# JPGENC0_CORE_MMU register map
Vendor: Texas Instruments
Peripheral module from a debugger description file (folder J722S).
Registers are 32-bit, read-only, reset values left out (the file's numbers can be read two ways) unless marked. A register's access mark holds for its fields unless they carry their own. Offsets are as the file gives them; lines under a group give offsets from that group; [hi:lo] are bit positions; {n}, {i} and the like mark numbered series; 'fields as' and 'values as' point back to an identical list; <NAME> marks a mode.

## JPGENC0_CORE_MMU
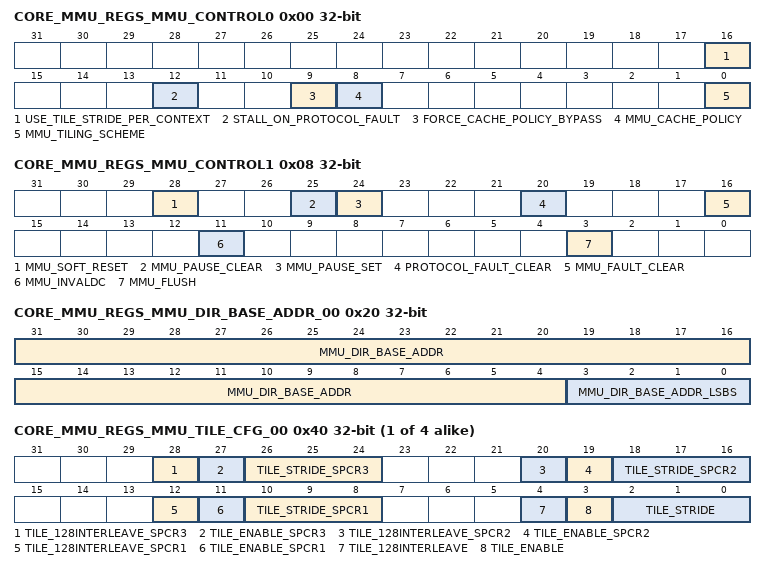
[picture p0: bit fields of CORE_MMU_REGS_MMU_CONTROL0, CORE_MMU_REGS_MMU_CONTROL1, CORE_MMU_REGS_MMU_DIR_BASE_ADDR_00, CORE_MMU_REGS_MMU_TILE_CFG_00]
0x00 CORE_MMU_REGS_MMU_CONTROL0 access per field
  [16] USE_TILE_STRIDE_PER_CONTEXT rw — 1: Separate MMU_TILE_CFG fields apply per context 0: All contexts use MMU_TILE_CFG for context 0
  [12] STALL_ON_PROTOCOL_FAULT rw — Debug only:Setting this bit to '1' causes any requestor with a protocol fault to stall
  [9] FORCE_CACHE_POLICY_BYPASS rw — Setting this bit to '1' causes all requests to external memory to have a cache policy of 0 [bypass], setting this bit to '0' passes internal cache policy to external interface
  [8] MMU_CACHE_POLICY rw — 1: MMU Directory/Page Table reads to be flagged as cacheable [external cache must have a way of flushing/tracking changes to Directory Table and Page Tables in host memory] 0: MMU reads to be flagged to bypass external cache
  [0] MMU_TILING_SCHEME rw — This bit controls the tiling scheme described in MMU Address Tiling section 0: Original tiling scheme [256-byte wide by 16 row tiles] 1: Alternative tiling scheme [512-byte wide by 8 row tiles]
0x08 CORE_MMU_REGS_MMU_CONTROL1 access per field
  [28] MMU_SOFT_RESET rw — Writing '1' to this bit causes all currently active or new memory requests to be discarded, so a reset of all active requestors is likely to also be required. External memory transactions will attempt to complete [including writing 0 data if a burst write request was sent but no corresponding data is available]. Writing '0' has no affect. Reading this field indicates if the soft reset is complete [this field will return to 0 when the soft reset is complete]
  [25] MMU_PAUSE_CLEAR rw — Writing '1' to this bit clears the pause bit, and allows new memory requests to resume. Writing '0' has no affect. Reading this field indicates if the pause bit is currently set. Setting both 'MMU_PAUSE_SET' and 'MMU_PAUSE_CLEAR' in the same write will clear the pause bit
  [24] MMU_PAUSE_SET rw — Writing '1' to this bit causes all new memory requests to pause [requests further down the pipeline will be allowed to complete]. Writing '0' has no affect. Reading this field indicates if the pause bit is currently set. Setting both 'MMU_PAUSE_SET' and 'MMU_PAUSE_CLEAR' in the same write will clear the pause bit
  [20] PROTOCOL_FAULT_CLEAR rw — Writing '1' to this bit clears all bus protocol fault flags. Writing '0' has no affect
  [16] MMU_FAULT_CLEAR rw — Writing '1' to this bit clears MMU fault [either page fault or read/write fault]. Writing '0' has no affect
  [11] MMU_INVALDC rw — For each 'dir_base_addr' used, writing '1' triggers invalidation[/flushing] of both the directory cache and page table cache for that 'dir_base_addr' [cached results for different 'dir_base_addr' can be invalidated/flushed independently]. Writing '0' has no affect
  [3] MMU_FLUSH rw — For each 'dir_base_addr' used, writing '1' triggers a flush of the Page Table cache and registered results for that 'dir_base_addr' [cached results for different 'dir_base_addr' can be flushed independently]. Writing '0' has no affect
0x10 CORE_MMU_REGS_MMU_BANK_INDEX
  [31:0] RESERVED — Specify which directory base address to use for 'group override' input n [If GROUP_OVERRIDE_SIZE is 0, this register is not used, otherwise there are '2 to the power GROUP_OVERRIDE_SIZE' entries supported in this register
0x14 CORE_MMU_REGS_EXT_REQUEST_PRIORITY_ENABLE access not given
0x18 CORE_MMU_REGS_REQUEST_PRIORITY_ENABLE
0x1C CORE_MMU_REGS_REQUEST_LIMITED_THROUGHPUT — RESERVED
0x20 CORE_MMU_REGS_MMU_DIR_BASE_ADDR_00 access per field
  [31:4] MMU_DIR_BASE_ADDR rw — Base address in physical memory for MMU Directory n Entries. When MMU_ENABLE_EXT_ADDRESSING is '1', the bits 31:0 are assigned to the address 31+EXT_ADDR_RANGE:0+EXT_ADDR_RANGE, but then any address offset within a page is forced to 0. When MMU_ENABLE_EXT_ADDRESSING is '0', bits 31:12 are assigned to address 31:12
  [3:0] MMU_DIR_BASE_ADDR_LSBS ro — Bits 3:0 of this register are read-only, and hardcoded in RTL at 0x0
{0x20+4i} CORE_MMU_REGS_MMU_DIR_BASE_ADDR_{i:02} (i=1..3)
  [31:0] MMU_DIR_BASE_ADDR — GROUP_OVERRIDE_SIZE hardcoded at 0 in RTL. Hence, this register is read only and returns 0x0
{0x40+4i} CORE_MMU_REGS_MMU_TILE_CFG_{i:02} access per field (i=0..3) — If USE_TILE_STRIDE_PER_CONTEXT is low, only the bottom byte of the register is used, and each of the four registers applies to the four regions defined by the corresponding MIN and MAX tile address ranges. If USE_TILE_STRIDE_PER_CONTEXT is high, the four bytes in a register applies to the four regions defined by the corresponding MIN and MAX tile address ranges. Then each of the four registers apply to four different contexts, where each context can use a different stride, but the MIN to MAX address range defining each region is common to all contexts (where context is the 2-bit index selected from the MMU_BANK_INDEX register).
  [28] TILE_128INTERLEAVE_SPCR3 rw — 0 : Customizable address manipulation of tiled accesses is not enabled 1 : Customizable address manipulation of tiled accesses is enabled
  [27] TILE_ENABLE_SPCR3 rw — 0 : Memory Tiling Disabled 1 : Memory Tiling Enabled
  [26:24] TILE_STRIDE_SPCR3 rw — Defines the X Tile Stride for the memory address range [stride is 2 to the power of [9+tile_stride+tiling_scheme]]
  [20] TILE_128INTERLEAVE_SPCR2 rw — 0 : Customizable address manipulation of tiled accesses is not enabled 1 : Customizable address manipulation of tiled accesses is enabled
  [19] TILE_ENABLE_SPCR2 rw — 0 : Memory Tiling Disabled 1 : Memory Tiling Enabled
  [18:16] TILE_STRIDE_SPCR2 rw — Defines the X Tile Stride for the memory address range [stride is 2 to the power of [9+tile_stride+tiling_scheme]]
  [12] TILE_128INTERLEAVE_SPCR1 rw — 0 : Customizable address manipulation of tiled accesses is not enabled 1 : Customizable address manipulation of tiled accesses is enabled
  [11] TILE_ENABLE_SPCR1 rw — 0 : Memory Tiling Disabled 1 : Memory Tiling Enabled
  [10:8] TILE_STRIDE_SPCR1 rw — Defines the X Tile Stride for the memory address range [stride is 2 to the power of [9+tile_stride+tiling_scheme]]
  [4] TILE_128INTERLEAVE rw — 0 : Customizable address manipulation of tiled accesses is not enabled 1 : Customizable address manipulation of tiled accesses is enabled
  [3] TILE_ENABLE rw — 0 : Memory Tiling Disabled 1 : Memory Tiling Enabled
  [2:0] TILE_STRIDE rw — Defines the X Tile Stride for the memory address range [stride is 2 to the power of [9+tile_stride+tiling_scheme]]
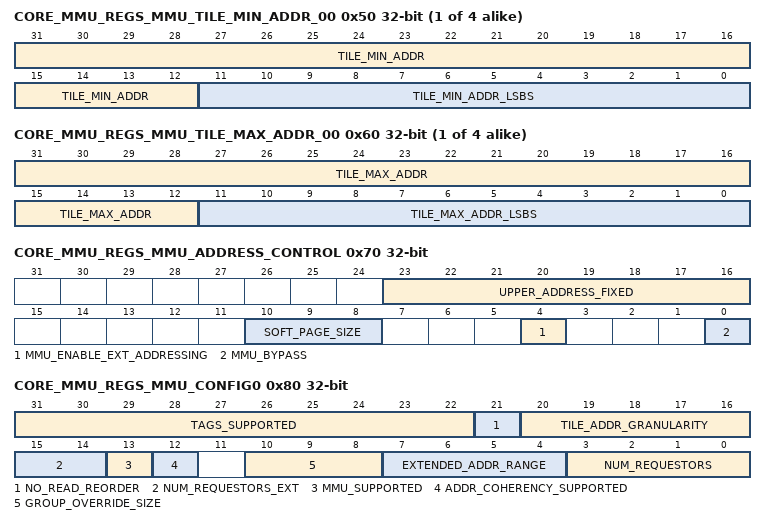
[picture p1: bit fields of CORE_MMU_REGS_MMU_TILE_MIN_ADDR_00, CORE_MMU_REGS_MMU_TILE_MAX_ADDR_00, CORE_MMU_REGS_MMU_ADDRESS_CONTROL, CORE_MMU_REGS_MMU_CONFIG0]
{0x50+4i} CORE_MMU_REGS_MMU_TILE_MIN_ADDR_{i:02} access per field (i=0..3)
  [31:12] TILE_MIN_ADDR rw — Defines the minimum address for tiling range, in terms of the virtual address MSB's i.e. 31:TILE_ADDR_GRANULARITY
  [11:0] TILE_MIN_ADDR_LSBS ro — TILE_ADDR_GRANULARITY is hardcoded in RTL at 12 [decimal]. Hence, bits 11:0 of this register are read-only, and hardcoded in RTL at 0x000
{0x60+4i} CORE_MMU_REGS_MMU_TILE_MAX_ADDR_{i:02} access per field (i=0..3)
  [31:12] TILE_MAX_ADDR rw — Defines the maximum address for tiling range, in terms of the virtual address MSB's i.e. 31:TILE_ADDR_GRANULARITY
  [11:0] TILE_MAX_ADDR_LSBS ro — TILE_ADDR_GRANULARITY is hardcoded in RTL at 12 [decimal]. Hence, bits 11:0 of this register are read-only, and hardcoded in RTL at 0x000
0x70 CORE_MMU_REGS_MMU_ADDRESS_CONTROL access per field
  [23:16] UPPER_ADDRESS_FIXED rw — If 'EXTENDED_ADDR_RANGE' is > 0, and MMU is used in bypass mode or MMU_ENABLE_EXT_ADDRESSING = '0', EXTENDED_ADDR_RANGE bits from this field will be used to define the state of the upper physical address bits [for all memory requests]
  [10:8] SOFT_PAGE_SIZE rw — This field selects MMU page size at run time [if this field is less than the minimum hardware configuration for PAGE_SIZE from MMU_CONFIG1, then the PAGE_SIZE will be used]
  [4] MMU_ENABLE_EXT_ADDRESSING rw — 1: Directory/Page Table entries loaded into MSBits of physical address bus 0: Directory/Page Table entries loaded into bits 31 downwards of physical address bus
  [0] MMU_BYPASS rw — 1: All memory requests bypass the 'Address Translation' part of the MMU, but tiling can still be enabled 0: All memory requests use of the 'Address Translation' part of the MMU
0x80 CORE_MMU_REGS_MMU_CONFIG0
  [31:22] TAGS_SUPPORTED — Number of outstanding bursts supported
  [21] NO_READ_REORDER — If this field is set, it indicates there is no read data re-ordering buffer [all requestors must accept read response out of order]
  [20:16] TILE_ADDR_GRANULARITY — This field indicates the granularity of the tile address range [where virtual address range is matched from [31:TILE_ADDR_GRANULARITY]]
  [15:14] NUM_REQUESTORS_EXT — In MMU version 4.2 onwards, NUM_REQUESTORS_EXT*16 + NUM_REQUESTORS indicates the number of requestors the core has been configured for [before version 4.2 this field was always 0]
  [13] MMU_SUPPORTED — This field indicates if MMU page table mapping is supported [N.B. tiling can still be used even if the MMU is not supported]
  [12] ADDR_COHERENCY_SUPPORTED — This field indicates if address coherency checking is supported [if it is not supported requestors need to use another mechanism to gurantee reads and writes to the same address don't occur out of order]
  [10:8] GROUP_OVERRIDE_SIZE — If this field is 0, only 1 directory base address is supported [MMU_DIR_BASE_ADDR0]. If this field is 1, only the first two entries in MMU_BANK_INDEX are used to select one of 4 base addresses. If this field is 2, there are 4 MMU_BANK_INDEX entries, 3 = 8 entries, 4 = 16 entries
  [7:4] EXTENDED_ADDR_RANGE — This field indicates the number of extended address bits [above 32] that the external memory interface uses
  [3:0] NUM_REQUESTORS — Before MMU version 4.2, this field indicates the number of requestors the core has been configured for [between 1 and 15, or a value of 0 =16 requestors]. In MMU version 4.2 onwards, this field + NUM_REQUESTORS_EXT*16 indicates the number of requestors the core has been configured for
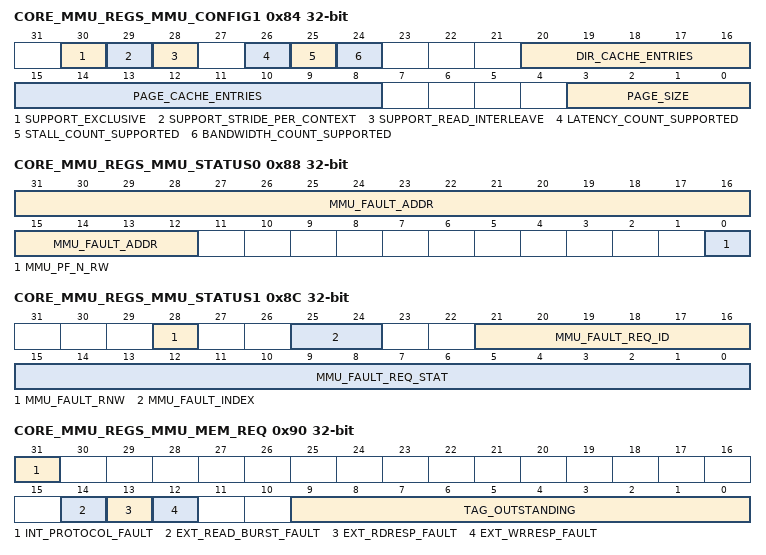
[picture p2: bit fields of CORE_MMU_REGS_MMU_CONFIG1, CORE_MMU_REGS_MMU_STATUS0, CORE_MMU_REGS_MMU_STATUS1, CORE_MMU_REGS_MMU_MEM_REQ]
0x84 CORE_MMU_REGS_MMU_CONFIG1
  [30] SUPPORT_EXCLUSIVE — Logic included to support exclusive transactions [for doing read-modify-write without another initiator modifying the value]
  [29] SUPPORT_STRIDE_PER_CONTEXT — Logic included to support separate tile stride per context
  [28] SUPPORT_READ_INTERLEAVE — Logic included to support interleaved read responses [violates Bus4 protocol but may occur when Bus4 to AXI bridge is used]
  [26] LATENCY_COUNT_SUPPORTED — Latency counts included
  [25] STALL_COUNT_SUPPORTED — Stall counts included
  [24] BANDWIDTH_COUNT_SUPPORTED — Bandwidth counts included
  [20:16] DIR_CACHE_ENTRIES — DIR_CACHE_ENTRIES * 128 defines the number of Directory Table entries which can be cached
  [15:8] PAGE_CACHE_ENTRIES — PAGE_CACHE_ENTRIES * 128 defines the number of Page Table entries which can be cached
  [3:0] PAGE_SIZE — Log2 MMU page size minus 12 [4kbyte page = 0, 16kbyte page = 2]
0x88 CORE_MMU_REGS_MMU_STATUS0
  [31:12] MMU_FAULT_ADDR — Page-aligned virtual address causing page fault
  [0] MMU_PF_N_RW — Indicates whether the current fault is a page fault [when high] or R/W protection fault [when low]
0x8C CORE_MMU_REGS_MMU_STATUS1
  [28] MMU_FAULT_RNW — Indicates if a read or write operation caused the current fault
  [25:24] MMU_FAULT_INDEX — Indicates the directory cache index of the current fault
  [21:16] MMU_FAULT_REQ_ID — Indicates the requestor ID of the request causing the current page fault
  [15:0] MMU_FAULT_REQ_STAT — 1-bit per requestor indicating if requestor triggered a page fault [in the event there are more than 16 requestors, modulo 16 arithmetic is used to assign 1 of these bits [i.e. requestor 1, 17, and 33 would all set bit 1]
0x90 CORE_MMU_REGS_MMU_MEM_REQ
  [31] INT_PROTOCOL_FAULT — When set, indicates the corresponding requestor had a bus protocol fault [excludes MMU requests]
  [14] EXT_READ_BURST_FAULT — When set, indicates the external interface returned a read burst for a tag which didn't contain the expected number of words
  [13] EXT_RDRESP_FAULT — When set, indicates the external interface returned a read response for a tag which wasn't outstanding [may occur after reset]
  [12] EXT_WRRESP_FAULT — When set, indicates the external interface returned a write response for a tag which wasn't outstanding [may occur after reset]
  [9:0] TAG_OUTSTANDING — Number of outstanding burst requests [TAGS which have been allocated but not yet freed, includes reads which have been returned but are still in the read re-order buffer]
0x94 CORE_MMU_REGS_MMU_MEM_EXT_OUTSTANDING
  [15:0] READ_WORDS_OUTSTANDING — Number of outstanding read words [in which read commands have been sent to the external interface, but the corresponding words haven't been received yet, counted in 'external data bus width' words]
0xA0 CORE_MMU_REGS_MMU_FAULT_SELECT access per field
  [3:0] MMU_FAULT_SELECT rw — The core can be configured to include protocol checkers on the input requestors, this field selects which interface is read from the PROTOCOL_FAULT register [0-15 = requestor 0-15]
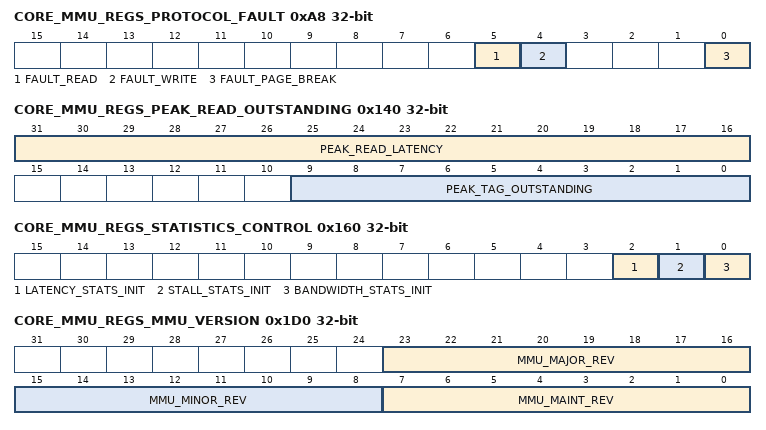
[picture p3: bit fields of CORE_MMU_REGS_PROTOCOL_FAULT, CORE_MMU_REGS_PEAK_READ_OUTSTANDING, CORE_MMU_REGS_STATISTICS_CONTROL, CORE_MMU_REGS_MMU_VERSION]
0xA8 CORE_MMU_REGS_PROTOCOL_FAULT
  [5] FAULT_READ — For requestor interface, indicates a read command on a requestor configured for write only
  [4] FAULT_WRITE — For requestor interface, indicates a write command on a requestor configured for read only
  [0] FAULT_PAGE_BREAK — The command crossed a page in the middle of a burst
0x100 CORE_MMU_REGS_TOTAL_READ_REQ — If MMU_CONFIG1.BANDWIDTH_COUNT_SUPPORTED is 0, this register will be fixed at 0.
  [31:0] TOTAL_READ_REQ — Debug only: Total number of bytes read
0x104 CORE_MMU_REGS_TOTAL_WRITE_REQ — If MMU_CONFIG1.BANDWIDTH_COUNT_SUPPORTED is 0, this register will be fixed at 0.
  [31:0] TOTAL_WRITE_REQ — Debug only: Total number of bytes written
0x108 CORE_MMU_REGS_READS_LESS_64_REQ — If MMU_CONFIG1.BANDWIDTH_COUNT_SUPPORTED is 0, this register will be fixed at 0.
  [31:0] READS_LESS_64_REQ — Debug only: Total number of bytes read using a burst size less than 64 bytes
0x10C CORE_MMU_REGS_WRITES_LESS_64_REQ — If MMU_CONFIG1.BANDWIDTH_COUNT_SUPPORTED is 0, this register will be fixed at 0.
  [31:0] WRITES_LESS_64_REQ — Debug only: Total number of bytes written using a burst size less than 64 bytes
0x120 CORE_MMU_REGS_EXT_CMD_STALL — If MMU_CONFIG1.STALL_COUNT_SUPPORTED is 0, this register will be fixed at 0.
  [31:0] EXT_CMD_STALL — Debug only: Number of cycles in which command out of Page Table lookup stalled by external interface
0x124 CORE_MMU_REGS_WRITE_REQ_STALL — If MMU_CONFIG1.STALL_COUNT_SUPPORTED is 0, this register will be fixed at 0.
  [31:0] WRITE_REQ_STALL — Debug only: Number of cycles in which command out of Page Table lookup stalled by write request FIFO
0x128 CORE_MMU_REGS_MMU_MISS_STALL — If MMU_CONFIG1.STALL_COUNT_SUPPORTED is 0, this register will be fixed at 0.
  [31:0] MMU_MISS_STALL — Debug only: Number of cycles in which command is stalled because MMU cache miss buffer is full
0x12C CORE_MMU_REGS_ADDRESS_STALL — If MMU_CONFIG1.STALL_COUNT_SUPPORTED is 0, this register will be fixed at 0.
  [31:0] ADDRESS_STALL — Debug only: Number of cycles in which command is stalled because Address coherency buffer is full
0x130 CORE_MMU_REGS_TAG_STALL — If MMU_CONFIG1.STALL_COUNT_SUPPORTED is 0, this register will be fixed at 0.
  [31:0] TAG_STALL — Debug only: Number of cycles in which command is stalled because no free TAGs to allocate
0x140 CORE_MMU_REGS_PEAK_READ_OUTSTANDING — If MMU_CONFIG1.LATENCY_COUNT_SUPPORTED is 0, this register will be fixed at 0.
  [31:16] PEAK_READ_LATENCY — Debug only: Peak read latency detected [number of cycles a read tag remains outstanding]
  [9:0] PEAK_TAG_OUTSTANDING — Debug only: Largest value on TAG_OUTSTANDING since last initialisation
0x144 CORE_MMU_REGS_AVERAGE_READ_LATENCY — If MMU_CONFIG1.LATENCY_COUNT_SUPPORTED is 0, this register will be fixed at 0.
  [31:0] AVERAGE_READ_LATENCY — Uses an IIR function on read latency, where the 16 MSBits are the same resolution as PEAK_READ_LATENCY
0x160 CORE_MMU_REGS_STATISTICS_CONTROL access per field
  [2] LATENCY_STATS_INIT rw — Writing '1' resets the latency statistics [this bit automatically clears to '0']
  [1] STALL_STATS_INIT rw — Writing '1' resets the stall count statistics [this bit automatically clears to '0']
  [0] BANDWIDTH_STATS_INIT rw — Writing '1' resets the bandwidth statistics [this bit automatically clears to '0']
0x1D0 CORE_MMU_REGS_MMU_VERSION
  [23:16] MMU_MAJOR_REV — MMU Major Revision
  [15:8] MMU_MINOR_REV — MMU Minor Revision
  [7:0] MMU_MAINT_REV — MMU Maintenance Revision
